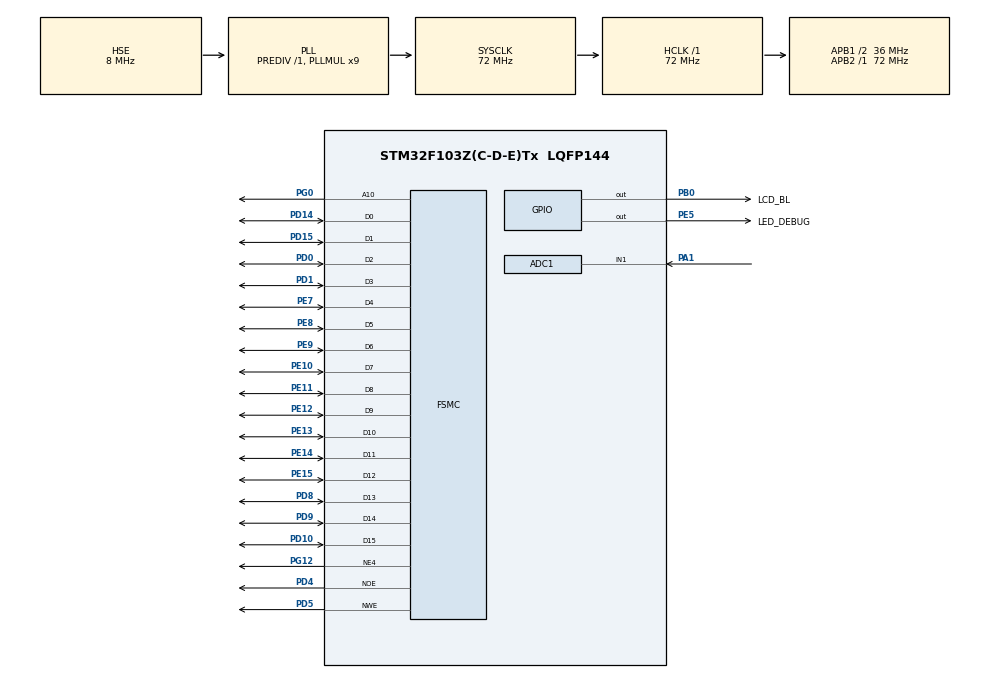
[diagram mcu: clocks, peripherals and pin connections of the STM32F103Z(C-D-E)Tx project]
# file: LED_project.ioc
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ADC1.Channel-0\#ChannelRegularConversion=ADC_CHANNEL_1
ADC1.ContinuousConvMode=DISABLE
ADC1.ExternalTrigConv=ADC_EXTERNALTRIGCONV_T3_TRGO
ADC1.NbrOfConversionFlag=1
ADC1.Rank-0\#ChannelRegularConversion=1
ADC1.SamplingTime-0\#ChannelRegularConversion=ADC_SAMPLETIME_239CYCLES_5
ADC1.master=1
Dma.ADC1.0.Direction=DMA_PERIPH_TO_MEMORY
Dma.ADC1.0.Instance=DMA1_Channel1
Dma.ADC1.0.MemDataAlignment=DMA_MDATAALIGN_HALFWORD
Dma.ADC1.0.MemInc=DMA_MINC_ENABLE
Dma.ADC1.0.Mode=DMA_CIRCULAR
Dma.ADC1.0.PeriphDataAlignment=DMA_PDATAALIGN_HALFWORD
Dma.ADC1.0.PeriphInc=DMA_PINC_DISABLE
Dma.ADC1.0.Priority=DMA_PRIORITY_LOW
Dma.Request0=ADC1
FSMC.AddressSetupTime4=2
FSMC.BusTurnAroundDuration4=0
FSMC.DataSetupTime4=16
FSMC.ExtendedAddressSetupTime4=4
FSMC.ExtendedBusTurnAroundDuration4=0
FSMC.ExtendedDataSetupTime4=9
FSMC.ExtendedMode4=FSMC_EXTENDED_MODE_ENABLE
Mcu.Family=STM32F1
Mcu.Name=STM32F103Z(C-D-E)Tx
Mcu.Package=LQFP144
NVIC.ADC1_2_IRQn=true\:0\:0\:false\:false\:true\:true\:true\:true
NVIC.DMA1_Channel1_IRQn=true\:0\:0\:false\:false\:true\:false\:true\:true
NVIC.PriorityGroup=NVIC_PRIORITYGROUP_4
OSC_IN.Mode=HSE-External-Oscillator
OSC_IN.Signal=RCC_OSC_IN
OSC_OUT.Mode=HSE-External-Oscillator
OSC_OUT.Signal=RCC_OSC_OUT
PA1.Signal=ADCx_IN1
PA13.Mode=Serial_Wire
PA13.Signal=SYS_JTMS-SWDIO
PA14.Mode=Serial_Wire
PA14.Signal=SYS_JTCK-SWCLK
PB0.GPIO_Label=LCD_BL
PB0.GPIO_PuPd=GPIO_PULLDOWN
PB0.Signal=GPIO_Output
PD0.GPIO_Mode=GPIO_MODE_AF_PP
PD0.Signal=FSMC_D2_DA2
PD1.GPIO_Mode=GPIO_MODE_AF_PP
PD1.Signal=FSMC_D3_DA3
PD10.GPIO_Mode=GPIO_MODE_AF_PP
PD10.Signal=FSMC_D15_DA15
PD14.GPIO_Mode=GPIO_MODE_AF_PP
PD14.Signal=FSMC_D0_DA0
PD15.GPIO_Mode=GPIO_MODE_AF_PP
PD15.Signal=FSMC_D1_DA1
PD4.GPIO_Mode=GPIO_MODE_AF_PP
PD4.Signal=FSMC_NOE
PD5.GPIO_Mode=GPIO_MODE_AF_PP
PD5.Signal=FSMC_NWE
PD8.GPIO_Mode=GPIO_MODE_AF_PP
PD8.Signal=FSMC_D13_DA13
PD9.GPIO_Mode=GPIO_MODE_AF_PP
PD9.Signal=FSMC_D14_DA14
PE10.GPIO_Mode=GPIO_MODE_AF_PP
PE10.Signal=FSMC_D7_DA7
PE11.GPIO_Mode=GPIO_MODE_AF_PP
PE11.Signal=FSMC_D8_DA8
PE12.GPIO_Mode=GPIO_MODE_AF_PP
PE12.Signal=FSMC_D9_DA9
PE13.GPIO_Mode=GPIO_MODE_AF_PP
PE13.Signal=FSMC_D10_DA10
PE14.GPIO_Mode=GPIO_MODE_AF_PP
PE14.Signal=FSMC_D11_DA11
PE15.GPIO_Mode=GPIO_MODE_AF_PP
PE15.Signal=FSMC_D12_DA12
PE5.GPIO_Label=LED_DEBUG
PE5.GPIO_PuPd=GPIO_PULLUP
PE5.PinState=GPIO_PIN_SET
PE5.Signal=GPIO_Output
PE7.GPIO_Mode=GPIO_MODE_AF_PP
PE7.Signal=FSMC_D4_DA4
PE8.GPIO_Mode=GPIO_MODE_AF_PP
PE8.Signal=FSMC_D5_DA5
PE9.GPIO_Mode=GPIO_MODE_AF_PP
PE9.Signal=FSMC_D6_DA6
PG0.GPIO_Mode=GPIO_MODE_AF_PP
PG0.Signal=FSMC_A10
PG12.GPIO_Mode=GPIO_MODE_AF_PP
PG12.Mode=NorPsramChipSelect4_4
PG12.Signal=FSMC_NE4
ProjectManager.HeapSize=0x200
ProjectManager.StackSize=0x400
ProjectManager.TargetToolchain=MDK-ARM V5.32
RCC.ADCPresc=RCC_ADCPCLK2_DIV6
RCC.AHBFreq_Value=72000000
RCC.APB1CLKDivider=RCC_HCLK_DIV2
RCC.APB1Freq_Value=36000000
RCC.APB1TimFreq_Value=72000000
RCC.APB2Freq_Value=72000000
RCC.APB2TimFreq_Value=72000000
RCC.HCLKFreq_Value=72000000
RCC.PLLMUL=RCC_PLL_MUL9
RCC.PLLSourceVirtual=RCC_PLLSOURCE_HSE
RCC.SYSCLKFreq_VALUE=72000000
RCC.SYSCLKSource=RCC_SYSCLKSOURCE_PLLCLK
RCC.USBFreq_Value=72000000
SH.ADCx_IN1.0=ADC1_IN1,IN1
SH.FSMC_A10.0=FSMC_A10,A10_4
SH.FSMC_D0_DA0.0=FSMC_D0,16b-d4
SH.FSMC_D10_DA10.0=FSMC_D10,16b-d4
SH.FSMC_D11_DA11.0=FSMC_D11,16b-d4
SH.FSMC_D12_DA12.0=FSMC_D12,16b-d4
SH.FSMC_D13_DA13.0=FSMC_D13,16b-d4
SH.FSMC_D14_DA14.0=FSMC_D14,16b-d4
SH.FSMC_D15_DA15.0=FSMC_D15,16b-d4
SH.FSMC_D1_DA1.0=FSMC_D1,16b-d4
SH.FSMC_D2_DA2.0=FSMC_D2,16b-d4
SH.FSMC_D3_DA3.0=FSMC_D3,16b-d4
SH.FSMC_D4_DA4.0=FSMC_D4,16b-d4
SH.FSMC_D5_DA5.0=FSMC_D5,16b-d4
SH.FSMC_D6_DA6.0=FSMC_D6,16b-d4
SH.FSMC_D7_DA7.0=FSMC_D7,16b-d4
SH.FSMC_D8_DA8.0=FSMC_D8,16b-d4
SH.FSMC_D9_DA9.0=FSMC_D9,16b-d4
SH.FSMC_NOE.0=FSMC_NOE,Lcd4
SH.FSMC_NWE.0=FSMC_NWE,Lcd4
TIM3.Prescaler=71
VP_TIM3_VS_ClockSourceINT.Mode=Internal
board=custom

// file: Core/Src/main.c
/* USER CODE BEGIN Header */
/**
  ******************************************************************************
  * @file           : main.c
  * @brief          : Main program body
  ******************************************************************************
  * @attention
  *
  * Copyright (c) 2024 STMicroelectronics.
  * All rights reserved.
  *
  * This software is licensed under terms that can be found in the LICENSE file
  * in the root directory of this software component.
  * If no LICENSE file comes with this software, it is provided AS-IS.
  *
  ******************************************************************************
  */
/* USER CODE END Header */
#include "main.h"
#include "adc.h"
#include "dma.h"
#include "tim.h"
#include "gpio.h"
#include "fsmc.h"

/* USER CODE BEGIN Includes */
#include "lcd.h"
/* USER CODE END Includes */

void SystemClock_Config(void);

int main(void)
{

  /* MCU Configuration--------------------------------------------------------*/

  /* Reset of all peripherals, Initializes the Flash interface and the Systick. */
  HAL_Init();

  /* Configure the system clock */
  SystemClock_Config();

  /* Initialize all configured peripherals */
  MX_GPIO_Init();
  MX_DMA_Init();
  MX_FSMC_Init();
  MX_ADC1_Init();
  MX_TIM3_Init();
  /* USER CODE BEGIN 2 */
  LCD_Init();
  LCD_DisplayOn();

  Osc_TFT_Windows();

  /* USER CODE END 2 */

  /* Infinite loop */
  /* USER CODE BEGIN WHILE */
  while (1)
  {
		 HAL_Delay(300);
		 HAL_Delay(300);
		 HAL_Delay(300);
		 HAL_Delay(300);
		 HAL_Delay(300);
      OS_ADC_DMA();
      HAL_Delay(300);
//      OS_ADC_Config();

    /* USER CODE END WHILE */

  }
}

void SystemClock_Config(void)
{
  RCC_OscInitTypeDef RCC_OscInitStruct = {0};
  RCC_ClkInitTypeDef RCC_ClkInitStruct = {0};
  RCC_PeriphCLKInitTypeDef PeriphClkInit = {0};

  /** Initializes the RCC Oscillators according to the specified parameters
  * in the RCC_OscInitTypeDef structure.
  */
  RCC_OscInitStruct.OscillatorType = RCC_OSCILLATORTYPE_HSE;
  RCC_OscInitStruct.HSEState = RCC_HSE_ON;
  RCC_OscInitStruct.HSEPredivValue = RCC_HSE_PREDIV_DIV1;
  RCC_OscInitStruct.HSIState = RCC_HSI_ON;
  RCC_OscInitStruct.PLL.PLLState = RCC_PLL_ON;
  RCC_OscInitStruct.PLL.PLLSource = RCC_PLLSOURCE_HSE;
  RCC_OscInitStruct.PLL.PLLMUL = RCC_PLL_MUL9;
  if (HAL_RCC_OscConfig(&RCC_OscInitStruct) != HAL_OK)
  {
    Error_Handler();
  }

  /** Initializes the CPU, AHB and APB buses clocks
  */
  RCC_ClkInitStruct.ClockType = RCC_CLOCKTYPE_HCLK|RCC_CLOCKTYPE_SYSCLK
                              |RCC_CLOCKTYPE_PCLK1|RCC_CLOCKTYPE_PCLK2;
  RCC_ClkInitStruct.SYSCLKSource = RCC_SYSCLKSOURCE_PLLCLK;
  RCC_ClkInitStruct.AHBCLKDivider = RCC_SYSCLK_DIV1;
  RCC_ClkInitStruct.APB1CLKDivider = RCC_HCLK_DIV2;
  RCC_ClkInitStruct.APB2CLKDivider = RCC_HCLK_DIV1;

  if (HAL_RCC_ClockConfig(&RCC_ClkInitStruct, FLASH_LATENCY_2) != HAL_OK)
  {
    Error_Handler();
  }
  PeriphClkInit.PeriphClockSelection = RCC_PERIPHCLK_ADC;
  PeriphClkInit.AdcClockSelection = RCC_ADCPCLK2_DIV6;
  if (HAL_RCCEx_PeriphCLKConfig(&PeriphClkInit) != HAL_OK)
  {
    Error_Handler();
  }
}

void Error_Handler(void)
{
  __disable_irq();
  while (1)
  {
  }
}
